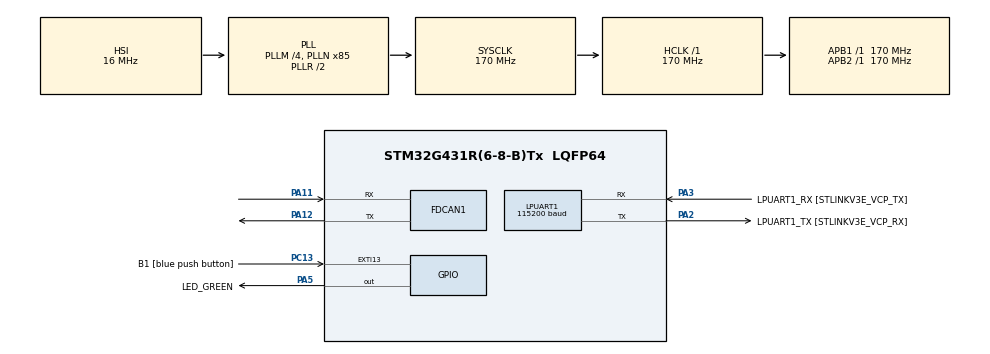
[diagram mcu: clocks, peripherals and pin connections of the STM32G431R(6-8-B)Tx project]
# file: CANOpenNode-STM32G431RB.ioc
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FDCAN1.AutoRetransmission=ENABLE
FDCAN1.DataPrescaler=3
FDCAN1.DataTimeSeg1=3
FDCAN1.DataTimeSeg2=3
FDCAN1.FrameFormat=FDCAN_FRAME_CLASSIC
FDCAN1.NominalPrescaler=3
FDCAN1.NominalSyncJumpWidth=3
FDCAN1.NominalTimeSeg1=42
FDCAN1.NominalTimeSeg2=14
FDCAN1.TransmitPause=DISABLE
LPUART1.BaudRate=115200
LPUART1.WordLength=UART_WORDLENGTH_8B
Mcu.Family=STM32G4
Mcu.Name=STM32G431R(6-8-B)Tx
Mcu.Package=LQFP64
NVIC.FDCAN1_IT0_IRQn=true\:0\:0\:false\:false\:false\:true\:true\:true
NVIC.FDCAN1_IT1_IRQn=true\:0\:0\:false\:false\:false\:true\:true\:true
NVIC.PriorityGroup=NVIC_PRIORITYGROUP_4
NVIC.TIM1_TRG_COM_TIM17_IRQn=true\:0\:0\:false\:false\:true\:true\:true\:true
PA11.Mode=FDCAN_Activate
PA11.Signal=FDCAN1_RX
PA12.Mode=FDCAN_Activate
PA12.Signal=FDCAN1_TX
PA13.GPIO_Label=T_SWDIO
PA13.Mode=Serial_Wire
PA13.Signal=SYS_JTMS-SWDIO
PA14.GPIO_Label=T_SWCLK
PA14.Mode=Serial_Wire
PA14.Signal=SYS_JTCK-SWCLK
PA2.GPIO_Label=LPUART1_TX [STLINKV3E_VCP_RX]
PA2.Mode=Asynchronous
PA2.Signal=LPUART1_TX
PA3.GPIO_Label=LPUART1_RX [STLINKV3E_VCP_TX]
PA3.Mode=Asynchronous
PA3.Signal=LPUART1_RX
PA5.GPIO_Label=LED_GREEN
PA5.Signal=GPIO_Output
PB3.GPIO_Label=T_SWO
PB3.Signal=SYS_JTDO-SWO
PC13.GPIO_Label=B1 [blue push button]
PC13.Signal=GPXTI13
PC14-OSC32_IN.Mode=LSE-External-Oscillator
PC14-OSC32_IN.Signal=RCC_OSC32_IN
PC15-OSC32_OUT.Mode=LSE-External-Oscillator
PC15-OSC32_OUT.Signal=RCC_OSC32_OUT
PF0-OSC_IN.Mode=HSE-External-Oscillator
PF0-OSC_IN.Signal=RCC_OSC_IN
PF1-OSC_OUT.Mode=HSE-External-Oscillator
PF1-OSC_OUT.Signal=RCC_OSC_OUT
ProjectManager.HeapSize=0x200
ProjectManager.StackSize=0x400
ProjectManager.TargetToolchain=STM32CubeIDE
RCC.ADC12Freq_Value=170000000
RCC.AHBFreq_Value=170000000
RCC.APB1Freq_Value=170000000
RCC.APB1TimFreq_Value=170000000
RCC.APB2Freq_Value=170000000
RCC.APB2TimFreq_Value=170000000
RCC.CortexFreq_Value=170000000
RCC.EXTERNAL_CLOCK_VALUE=12288000
RCC.HCLKFreq_Value=170000000
RCC.HSE_VALUE=24000000
RCC.HSI48_VALUE=48000000
RCC.HSICalibrationValue=64
RCC.HSI_VALUE=16000000
RCC.LSE_Drive_Capability=RCC_LSEDRIVE_LOW
RCC.PLLM=RCC_PLLM_DIV4
RCC.PLLN=85
RCC.PREFETCH_ENABLE=0
RCC.RTCClockSelection=RCC_RTCCLKSOURCE_LSE
RCC.SYSCLKFreq_VALUE=170000000
RCC.SYSCLKSource=RCC_SYSCLKSOURCE_PLLCLK
RCC.USBFreq_Value=170000000
RCC.VCOOutputFreq_Value=340000000
TIM17.PeriodNoDither=999
TIM17.Prescaler=63
VP_RTC_VS_RTC_Activate.Mode=RTC_Enabled
VP_SYS_VS_DBSignals.Mode=DisableDeadBatterySignals
VP_TIM17_VS_ClockSourceINT.Mode=Enable_Timer
board=NUCLEO-G431RB

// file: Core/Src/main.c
/* USER CODE BEGIN Header */
/**
  ******************************************************************************
  * @file           : main.c
  * @brief          : Main program body
  ******************************************************************************
  * @attention
  *
  * Copyright (c) 2022 STMicroelectronics.
  * All rights reserved.
  *
  * This software is licensed under terms that can be found in the LICENSE file
  * in the root directory of this software component.
  * If no LICENSE file comes with this software, it is provided AS-IS.
  *
  ******************************************************************************
  */
/* USER CODE END Header */
#include "main.h"
#include "fdcan.h"
#include "usart.h"
#include "rtc.h"
#include "tim.h"
#include "gpio.h"

void SystemClock_Config(void);

int main(void)
{

  /* MCU Configuration--------------------------------------------------------*/

  /* Reset of all peripherals, Initializes the Flash interface and the Systick. */
  HAL_Init();

  /* Configure the system clock */
  SystemClock_Config();

  /* Initialize all configured peripherals */
  MX_GPIO_Init();
  MX_FDCAN1_Init();
  MX_LPUART1_UART_Init();
  MX_RTC_Init();
  MX_TIM17_Init();
  /* USER CODE BEGIN 2 */
  main_canopen();
  /* USER CODE END 2 */

  /* Infinite loop */
  while (1)
  {

  }
}

void SystemClock_Config(void)
{
  RCC_OscInitTypeDef RCC_OscInitStruct = {0};
  RCC_ClkInitTypeDef RCC_ClkInitStruct = {0};

  /** Configure the main internal regulator output voltage
  */
  HAL_PWREx_ControlVoltageScaling(PWR_REGULATOR_VOLTAGE_SCALE1_BOOST);

  /** Configure LSE Drive Capability
  */
  HAL_PWR_EnableBkUpAccess();
  __HAL_RCC_LSEDRIVE_CONFIG(RCC_LSEDRIVE_LOW);

  /** Initializes the RCC Oscillators according to the specified parameters
  * in the RCC_OscInitTypeDef structure.
  */
  RCC_OscInitStruct.OscillatorType = RCC_OSCILLATORTYPE_HSI|RCC_OSCILLATORTYPE_LSE;
  RCC_OscInitStruct.LSEState = RCC_LSE_ON;
  RCC_OscInitStruct.HSIState = RCC_HSI_ON;
  RCC_OscInitStruct.HSICalibrationValue = RCC_HSICALIBRATION_DEFAULT;
  RCC_OscInitStruct.PLL.PLLState = RCC_PLL_ON;
  RCC_OscInitStruct.PLL.PLLSource = RCC_PLLSOURCE_HSI;
  RCC_OscInitStruct.PLL.PLLM = RCC_PLLM_DIV4;
  RCC_OscInitStruct.PLL.PLLN = 85;
  RCC_OscInitStruct.PLL.PLLP = RCC_PLLP_DIV2;
  RCC_OscInitStruct.PLL.PLLQ = RCC_PLLQ_DIV2;
  RCC_OscInitStruct.PLL.PLLR = RCC_PLLR_DIV2;
  if (HAL_RCC_OscConfig(&RCC_OscInitStruct) != HAL_OK)
  {
    Error_Handler();
  }

  /** Initializes the CPU, AHB and APB buses clocks
  */
  RCC_ClkInitStruct.ClockType = RCC_CLOCKTYPE_HCLK|RCC_CLOCKTYPE_SYSCLK
                              |RCC_CLOCKTYPE_PCLK1|RCC_CLOCKTYPE_PCLK2;
  RCC_ClkInitStruct.SYSCLKSource = RCC_SYSCLKSOURCE_PLLCLK;
  RCC_ClkInitStruct.AHBCLKDivider = RCC_SYSCLK_DIV1;
  RCC_ClkInitStruct.APB1CLKDivider = RCC_HCLK_DIV1;
  RCC_ClkInitStruct.APB2CLKDivider = RCC_HCLK_DIV1;

  if (HAL_RCC_ClockConfig(&RCC_ClkInitStruct, FLASH_LATENCY_4) != HAL_OK)
  {
    Error_Handler();
  }
}

void Error_Handler(void)
{
  __disable_irq();
  while (1)
  {
  }
}
